# STM32F107xx register map
File version: 1.2
CPU: 
Registers are 32-bit, read-write, reset 0x0 unless marked. A register's access mark holds for its fields unless they carry their own. Offsets are from the block's base; [hi:lo] are bit positions; {n}, {i} and the like mark numbered series; 'fields as' and 'values as' point back to an identical list.

## EXTI
Base 0x40010400
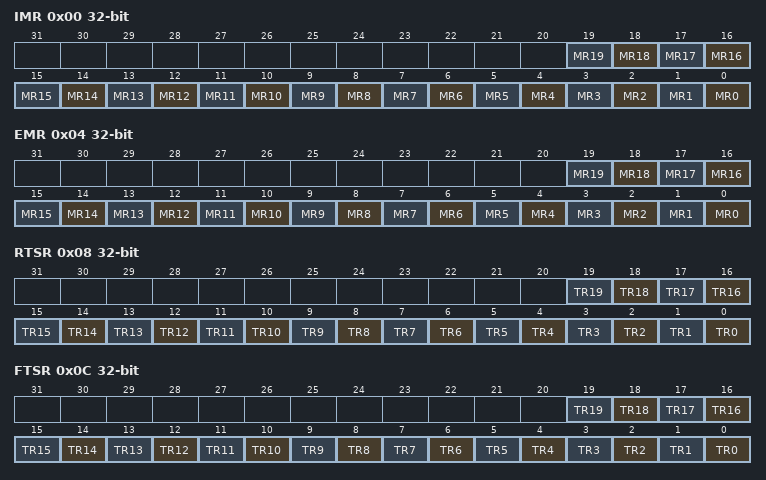
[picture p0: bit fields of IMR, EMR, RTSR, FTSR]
0x00 IMR — Interrupt mask register (EXTI_IMR)
  [n] MR{n} (n=0..19) — Interrupt Mask on line {n}
0x04 EMR — Event mask register (EXTI_EMR)
  [n] MR{n} (n=0..19) — Event Mask on line {n}
0x08 RTSR — Rising Trigger selection register (EXTI_RTSR)
  [n] TR{n} (n=0..19) — Rising trigger event configuration of line {n}
0x0C FTSR — Falling Trigger selection register (EXTI_FTSR)
  [n] TR{n} (n=0..19) — Falling trigger event configuration of line {n}
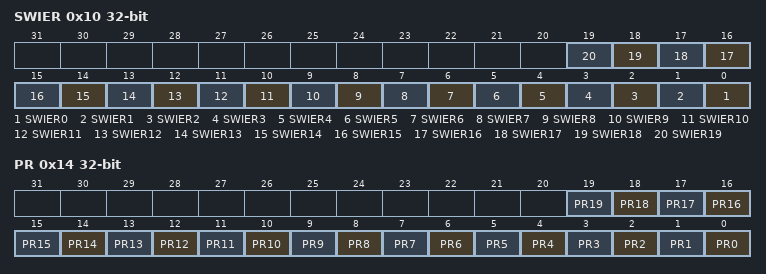
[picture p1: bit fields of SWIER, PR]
0x10 SWIER — Software interrupt event register (EXTI_SWIER)
  [n] SWIER{n} (n=0..19) — Software Interrupt on line {n}
0x14 PR — Pending register (EXTI_PR)
  [n] PR{n} (n=0..19) — Pending bit {n}

## DMA1 — DMA controller
Base 0x40020000
Same registers: DMA2 0x40020400
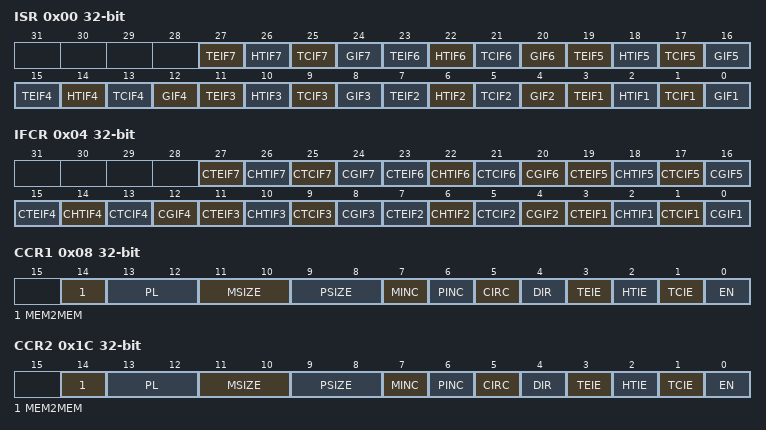
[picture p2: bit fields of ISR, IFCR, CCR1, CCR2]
0x00 ISR ro — DMA interrupt status register (DMA_ISR)
  [4n-1] TEIF{n} (n=1..7) — Channel {n} Transfer Error flag
  [4n-2] HTIF{n} (n=1..7) — Channel {n} Half Transfer Complete flag
  [4n-3] TCIF{n} (n=1..7) — Channel {n} Transfer Complete flag
  [4n-4] GIF{n} (n=1..7) — Channel {n} Global interrupt flag
0x04 IFCR wo — DMA interrupt flag clear register (DMA_IFCR)
  [4n-1] CTEIF{n} (n=1..7) — Channel {n} Transfer Error clear
  [4n-2] CHTIF{n} (n=1..7) — Channel {n} Half Transfer clear
  [4n-3] CTCIF{n} (n=1..7) — Channel {n} Transfer Complete clear
  [4n-4] CGIF{n} (n=1..7) — Channel {n} Global interrupt clear
0x08 CCR1 — DMA channel configuration register (DMA_CCR)
  [14] MEM2MEM — Memory to memory mode
  [13:12] PL — Channel Priority level
  [11:10] MSIZE — Memory size
  [9:8] PSIZE — Peripheral size
  [7] MINC — Memory increment mode
  [6] PINC — Peripheral increment mode
  [5] CIRC — Circular mode
  [4] DIR — Data transfer direction
  [3] TEIE — Transfer error interrupt enable
  [2] HTIE — Half Transfer interrupt enable
  [1] TCIE — Transfer complete interrupt enable
  [0] EN — Channel enable
0x0C CNDTR1 — DMA channel 1 number of data register
  [15:0] NDT — Number of data to transfer
0x10 CPAR1 — DMA channel 1 peripheral address register
  [31:0] PA — Peripheral address
{0x0+0x14*i} CMAR{i} (i=1..7) — DMA channel {i} memory address register
  [31:0] MA — Memory address
0x1C CCR2 — DMA channel configuration register (DMA_CCR)
  fields as CCR1
0x20 CNDTR2 — DMA channel 2 number of data register
  [15:0] NDT — Number of data to transfer
0x24 CPAR2 — DMA channel 2 peripheral address register
  [31:0] PA — Peripheral address
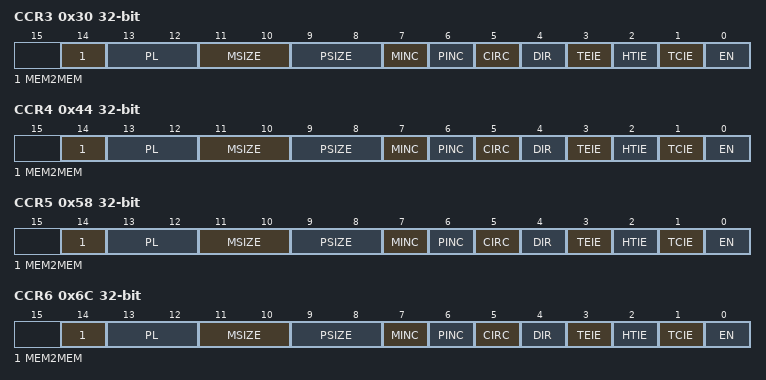
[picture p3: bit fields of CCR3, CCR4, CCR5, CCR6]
0x30 CCR3 — DMA channel configuration register (DMA_CCR)
  fields as CCR1
0x34 CNDTR3 — DMA channel 3 number of data register
  [15:0] NDT — Number of data to transfer
0x38 CPAR3 — DMA channel 3 peripheral address register
  [31:0] PA — Peripheral address
0x44 CCR4 — DMA channel configuration register (DMA_CCR)
  fields as CCR1
0x48 CNDTR4 — DMA channel 4 number of data register
  [15:0] NDT — Number of data to transfer
0x4C CPAR4 — DMA channel 4 peripheral address register
  [31:0] PA — Peripheral address
0x58 CCR5 — DMA channel configuration register (DMA_CCR)
  fields as CCR1
0x5C CNDTR5 — DMA channel 5 number of data register
  [15:0] NDT — Number of data to transfer
0x60 CPAR5 — DMA channel 5 peripheral address register
  [31:0] PA — Peripheral address
0x6C CCR6 — DMA channel configuration register (DMA_CCR)
  fields as CCR1
0x70 CNDTR6 — DMA channel 6 number of data register
  [15:0] NDT — Number of data to transfer
0x74 CPAR6 — DMA channel 6 peripheral address register
  [31:0] PA — Peripheral address
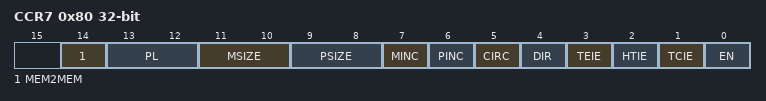
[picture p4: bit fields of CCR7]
0x80 CCR7 — DMA channel configuration register (DMA_CCR)
  fields as CCR1
0x84 CNDTR7 — DMA channel 7 number of data register
  [15:0] NDT — Number of data to transfer
0x88 CPAR7 — DMA channel 7 peripheral address register
  [31:0] PA — Peripheral address

## RTC — Real time clock
Base 0x40002800
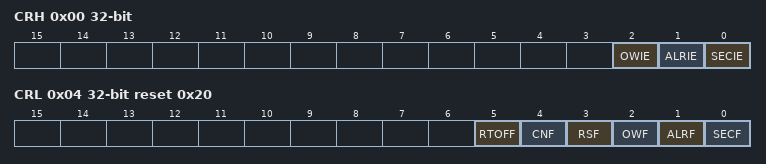
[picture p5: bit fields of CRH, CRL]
0x00 CRH — RTC Control Register High
  [2] OWIE — Overflow interrupt Enable
  [1] ALRIE — Alarm interrupt Enable
  [0] SECIE — Second interrupt Enable
0x04 CRL access per field reset 0x20 — RTC Control Register Low
  [5] RTOFF ro — RTC operation OFF
  [4] CNF rw — Configuration Flag
  [3] RSF rw — Registers Synchronized Flag
  [2] OWF rw — Overflow Flag
  [1] ALRF rw — Alarm Flag
  [0] SECF rw — Second Flag
0x08 PRLH wo — RTC Prescaler Load Register High
  [3:0] PRLH
0x0C PRLL wo reset 0x8000 — RTC Prescaler Load Register Low
  [15:0] PRLL — RTC Prescaler Divider Register Low
0x10 DIVH ro — RTC Prescaler Divider Register High
  [3:0] DIVH — RTC prescaler divider register high
0x14 DIVL ro reset 0x8000 — RTC Prescaler Divider Register Low
  [15:0] DIVL — RTC prescaler divider register Low
0x18 CNTH — RTC Counter Register High
  [15:0] CNTH — RTC counter register high
0x1C CNTL — RTC Counter Register Low
  [15:0] CNTL — RTC counter register Low
0x20 ALRH wo reset 0xFFFF — RTC Alarm Register High
  [15:0] ALRH — RTC alarm register high
0x24 ALRL wo reset 0xFFFF — RTC Alarm Register Low
  [15:0] ALRL — RTC alarm register low
